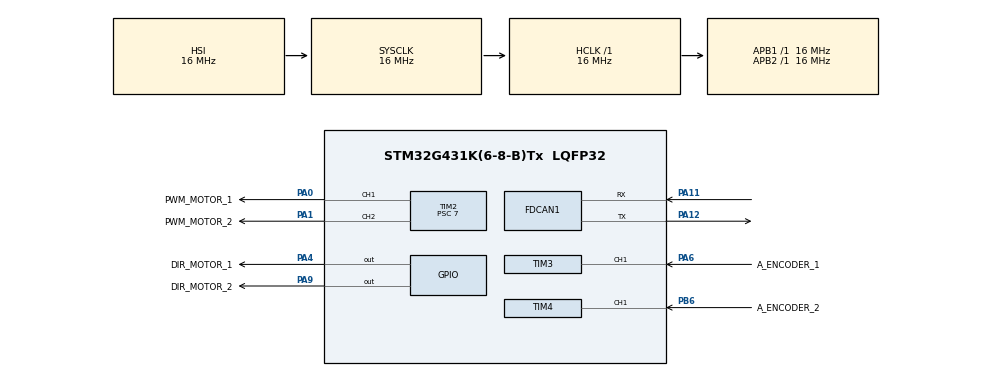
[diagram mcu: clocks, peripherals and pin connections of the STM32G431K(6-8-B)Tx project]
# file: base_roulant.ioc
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FDCAN1.CalculateBaudRateNominal=125000
FDCAN1.CalculateTimeBitNominal=8000
FDCAN1.CalculateTimeQuantumNominal=1000.0
FDCAN1.ClockDivider=FDCAN_CLOCK_DIV2
FDCAN1.NominalPrescaler=8
FDCAN1.NominalTimeSeg1=3
FDCAN1.NominalTimeSeg2=4
FDCAN1.StdFiltersNbr=1
Mcu.Family=STM32G4
Mcu.Name=STM32G431K(6-8-B)Tx
Mcu.Package=LQFP32
NVIC.PriorityGroup=NVIC_PRIORITYGROUP_4
NVIC.TIM1_UP_TIM16_IRQn=true\:0\:0\:true\:false\:true\:true\:true\:true
NVIC.TIM3_IRQn=true\:0\:0\:true\:false\:true\:true\:true\:true
NVIC.TIM4_IRQn=true\:0\:0\:true\:false\:true\:true\:true\:true
PA0.GPIO_Label=PWM_MOTOR_1
PA0.Signal=S_TIM2_CH1
PA1.GPIO_Label=PWM_MOTOR_2
PA1.Signal=S_TIM2_CH2
PA11.Mode=FDCAN_Activate
PA11.Signal=FDCAN1_RX
PA12.Mode=FDCAN_Activate
PA12.Signal=FDCAN1_TX
PA4.GPIO_Label=DIR_MOTOR_1
PA4.Signal=GPIO_Output
PA6.GPIO_Label=A_ENCODER_1
PA6.Signal=S_TIM3_CH1
PA9.GPIO_Label=DIR_MOTOR_2
PA9.Signal=GPIO_Output
PB6.GPIO_Label=A_ENCODER_2
PB6.Signal=S_TIM4_CH1
ProjectManager.HeapSize=0x200
ProjectManager.StackSize=0x400
ProjectManager.TargetToolchain=STM32CubeIDE
RCC.AHBFreq_Value=16000000
RCC.APB1Freq_Value=16000000
RCC.APB1TimFreq_Value=16000000
RCC.APB2Freq_Value=16000000
RCC.APB2TimFreq_Value=16000000
RCC.CortexFreq_Value=16000000
RCC.EXTERNAL_CLOCK_VALUE=12288000
RCC.HCLKFreq_Value=16000000
RCC.HSE_VALUE=8000000
RCC.HSI48_VALUE=48000000
RCC.HSI_VALUE=16000000
RCC.LSE_VALUE=32768
RCC.SYSCLKFreq_VALUE=16000000
RCC.USBFreq_Value=64000000
RCC.VCOOutputFreq_Value=128000000
SH.S_TIM2_CH1.0=TIM2_CH1,PWM Generation1 CH1
SH.S_TIM2_CH2.0=TIM2_CH2,PWM Generation2 CH2
SH.S_TIM3_CH1.0=TIM3_CH1,Input_Capture1_from_TI1
SH.S_TIM4_CH1.0=TIM4_CH1,Input_Capture1_from_TI1
TIM1.PeriodNoDither=3999
TIM1.Prescaler=2
TIM2.Channel-PWM\ Generation1\ CH1=TIM_CHANNEL_1
TIM2.Channel-PWM\ Generation2\ CH2=TIM_CHANNEL_2
TIM2.PeriodNoDither=99
TIM2.Prescaler=7
TIM3.Channel-Input_Capture1_from_TI1=TIM_CHANNEL_1
TIM3.Prescaler=127
TIM4.Channel-Input_Capture1_from_TI1=TIM_CHANNEL_1
TIM4.Prescaler=127
VP_SYS_VS_DBSignals.Mode=DisableDeadBatterySignals
VP_TIM1_VS_ClockSourceINT.Mode=Internal
VP_TIM2_VS_ClockSourceINT.Mode=Internal
board=custom

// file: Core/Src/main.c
/* USER CODE BEGIN Header */
/**
  ******************************************************************************
  * @file           : main.c
  * @brief          : Main program body
  ******************************************************************************
  * @attention
  *
  * Copyright (c) 2023 STMicroelectronics.
  * All rights reserved.
  *
  * This software is licensed under terms that can be found in the LICENSE file
  * in the root directory of this software component.
  * If no LICENSE file comes with this software, it is provided AS-IS.
  *
  ******************************************************************************
  */
/* USER CODE END Header */
#include "main.h"

/* USER CODE BEGIN Includes */
#include "base_roulant.h"
#include "can_stm32.h"
/* USER CODE END Includes */

/* USER CODE BEGIN PD */
#define TIM_CHANNEL_MOTOR_LEFT TIM_CHANNEL_1
#define TIM_CHANNEL_MOTOR_RIGHT TIM_CHANNEL_2

/* USER CODE END PD */

FDCAN_HandleTypeDef hfdcan1;

TIM_HandleTypeDef htim1;
TIM_HandleTypeDef htim2;
TIM_HandleTypeDef htim3;
TIM_HandleTypeDef htim4;

/* USER CODE BEGIN PV */
float s_left = 0;
float s_right = 0;

/* USER CODE END PV */

void SystemClock_Config(void);
static void MX_GPIO_Init(void);
static void MX_TIM2_Init(void);
static void MX_TIM3_Init(void);
static void MX_TIM4_Init(void);
static void MX_TIM1_Init(void);
static void MX_FDCAN1_Init(void);

/* USER CODE BEGIN 0 */
uint8_t dataTest[8] = {1,2,3,4,5,6,7,8};
/* USER CODE END 0 */

int main(void)
{

  /* MCU Configuration--------------------------------------------------------*/

  /* Reset of all peripherals, Initializes the Flash interface and the Systick. */
  HAL_Init();

  /* Configure the system clock */
  SystemClock_Config();

  /* Initialize all configured peripherals */
  MX_GPIO_Init();
  MX_TIM2_Init();
  MX_TIM3_Init();
  MX_TIM4_Init();
  MX_TIM1_Init();
  MX_FDCAN1_Init();
  /* USER CODE BEGIN 2 */
  BR_init(&htim1 ,&htim2, TIM_CHANNEL_MOTOR_LEFT, &htim2, TIM_CHANNEL_MOTOR_RIGHT, DIR_MOTOR_1_GPIO_Port, DIR_MOTOR_1_Pin, DIR_MOTOR_2_GPIO_Port, DIR_MOTOR_2_Pin, &htim3, &htim4, &hfdcan1);

  // Test sequence
  /*
  BR_setSpeed(BR_MOTOR_LEFT, 320.0);
  HAL_Delay(10000);
  BR_setSpeed(BR_MOTOR_LEFT, 20.0);
  HAL_Delay(30000);
  BR_setSpeed(BR_MOTOR_LEFT, 500.0);
  HAL_Delay(10000);
  BR_setSpeed(BR_MOTOR_LEFT, 0.0);
  HAL_Delay(10000);
	*/

  //BR_setPWM(BR_MOTOR_LEFT, 50);
  //BR_setPWM(BR_MOTOR_RIGHT, 50);
//  HAL_Delay(10000);

  //BR_setPWM(BR_MOTOR_LEFT, 30);
  //BR_setPWM(BR_MOTOR_RIGHT, 30);

//  s_left = BR_getSpeed(BR_MOTOR_LEFT);
//  s_right = BR_getSpeed(BR_MOTOR_RIGHT);
//
//  HAL_Delay(20000);
//
//  BR_stopAllMotors();

  /* USER CODE END 2 */

  /* Infinite loop */
  /* USER CODE BEGIN WHILE */
  while (1)
  {
	  //s_left = BR_getSpeed(BR_MOTOR_LEFT);
	  //s_right = BR_getSpeed(BR_MOTOR_RIGHT);

    /* Uncomment to ge CMD from CAN */
	  BR_getCMDfromCAN();
    /********************************/

	  //CAN_sendBackPing(CAN_ID_MASTER);
	  //CAN_send(dataTest, 0, 1);
	  HAL_Delay(10);
    /* USER CODE END WHILE */

  }
}

void SystemClock_Config(void)
{
  RCC_OscInitTypeDef RCC_OscInitStruct = {0};
  RCC_ClkInitTypeDef RCC_ClkInitStruct = {0};

  /** Configure the main internal regulator output voltage
  */
  HAL_PWREx_ControlVoltageScaling(PWR_REGULATOR_VOLTAGE_SCALE1);

  /** Initializes the RCC Oscillators according to the specified parameters
  * in the RCC_OscInitTypeDef structure.
  */
  RCC_OscInitStruct.OscillatorType = RCC_OSCILLATORTYPE_HSI;
  RCC_OscInitStruct.HSIState = RCC_HSI_ON;
  RCC_OscInitStruct.HSICalibrationValue = RCC_HSICALIBRATION_DEFAULT;
  RCC_OscInitStruct.PLL.PLLState = RCC_PLL_NONE;
  if (HAL_RCC_OscConfig(&RCC_OscInitStruct) != HAL_OK)
  {
    Error_Handler();
  }

  /** Initializes the CPU, AHB and APB buses clocks
  */
  RCC_ClkInitStruct.ClockType = RCC_CLOCKTYPE_HCLK|RCC_CLOCKTYPE_SYSCLK
                              |RCC_CLOCKTYPE_PCLK1|RCC_CLOCKTYPE_PCLK2;
  RCC_ClkInitStruct.SYSCLKSource = RCC_SYSCLKSOURCE_HSI;
  RCC_ClkInitStruct.AHBCLKDivider = RCC_SYSCLK_DIV1;
  RCC_ClkInitStruct.APB1CLKDivider = RCC_HCLK_DIV1;
  RCC_ClkInitStruct.APB2CLKDivider = RCC_HCLK_DIV1;

  if (HAL_RCC_ClockConfig(&RCC_ClkInitStruct, FLASH_LATENCY_0) != HAL_OK)
  {
    Error_Handler();
  }
}

static void MX_FDCAN1_Init(void)
{

  hfdcan1.Instance = FDCAN1;
  hfdcan1.Init.ClockDivider = FDCAN_CLOCK_DIV2;
  hfdcan1.Init.FrameFormat = FDCAN_FRAME_CLASSIC;
  hfdcan1.Init.Mode = FDCAN_MODE_NORMAL;
  hfdcan1.Init.AutoRetransmission = DISABLE;
  hfdcan1.Init.TransmitPause = DISABLE;
  hfdcan1.Init.ProtocolException = DISABLE;
  hfdcan1.Init.NominalPrescaler = 8;
  hfdcan1.Init.NominalSyncJumpWidth = 1;
  hfdcan1.Init.NominalTimeSeg1 = 3;
  hfdcan1.Init.NominalTimeSeg2 = 4;
  hfdcan1.Init.DataPrescaler = 1;
  hfdcan1.Init.DataSyncJumpWidth = 1;
  hfdcan1.Init.DataTimeSeg1 = 1;
  hfdcan1.Init.DataTimeSeg2 = 1;
  hfdcan1.Init.StdFiltersNbr = 1;
  hfdcan1.Init.ExtFiltersNbr = 0;
  hfdcan1.Init.TxFifoQueueMode = FDCAN_TX_FIFO_OPERATION;
  if (HAL_FDCAN_Init(&hfdcan1) != HAL_OK)
  {
    Error_Handler();
  }

}

static void MX_TIM1_Init(void)
{

  TIM_ClockConfigTypeDef sClockSourceConfig = {0};
  TIM_MasterConfigTypeDef sMasterConfig = {0};

  htim1.Instance = TIM1;
  htim1.Init.Prescaler = 2;
  htim1.Init.CounterMode = TIM_COUNTERMODE_UP;
  htim1.Init.Period = 3999;
  htim1.Init.ClockDivision = TIM_CLOCKDIVISION_DIV1;
  htim1.Init.RepetitionCounter = 0;
  htim1.Init.AutoReloadPreload = TIM_AUTORELOAD_PRELOAD_DISABLE;
  if (HAL_TIM_Base_Init(&htim1) != HAL_OK)
  {
    Error_Handler();
  }
  sClockSourceConfig.ClockSource = TIM_CLOCKSOURCE_INTERNAL;
  if (HAL_TIM_ConfigClockSource(&htim1, &sClockSourceConfig) != HAL_OK)
  {
    Error_Handler();
  }
  sMasterConfig.MasterOutputTrigger = TIM_TRGO_RESET;
  sMasterConfig.MasterOutputTrigger2 = TIM_TRGO2_RESET;
  sMasterConfig.MasterSlaveMode = TIM_MASTERSLAVEMODE_DISABLE;
  if (HAL_TIMEx_MasterConfigSynchronization(&htim1, &sMasterConfig) != HAL_OK)
  {
    Error_Handler();
  }

}

static void MX_TIM2_Init(void)
{

  TIM_ClockConfigTypeDef sClockSourceConfig = {0};
  TIM_MasterConfigTypeDef sMasterConfig = {0};
  TIM_OC_InitTypeDef sConfigOC = {0};

  htim2.Instance = TIM2;
  htim2.Init.Prescaler = 7;
  htim2.Init.CounterMode = TIM_COUNTERMODE_UP;
  htim2.Init.Period = 99;
  htim2.Init.ClockDivision = TIM_CLOCKDIVISION_DIV1;
  htim2.Init.AutoReloadPreload = TIM_AUTORELOAD_PRELOAD_DISABLE;
  if (HAL_TIM_Base_Init(&htim2) != HAL_OK)
  {
    Error_Handler();
  }
  sClockSourceConfig.ClockSource = TIM_CLOCKSOURCE_INTERNAL;
  if (HAL_TIM_ConfigClockSource(&htim2, &sClockSourceConfig) != HAL_OK)
  {
    Error_Handler();
  }
  if (HAL_TIM_PWM_Init(&htim2) != HAL_OK)
  {
    Error_Handler();
  }
  sMasterConfig.MasterOutputTrigger = TIM_TRGO_RESET;
  sMasterConfig.MasterSlaveMode = TIM_MASTERSLAVEMODE_DISABLE;
  if (HAL_TIMEx_MasterConfigSynchronization(&htim2, &sMasterConfig) != HAL_OK)
  {
    Error_Handler();
  }
  sConfigOC.OCMode = TIM_OCMODE_PWM1;
  sConfigOC.Pulse = 0;
  sConfigOC.OCPolarity = TIM_OCPOLARITY_HIGH;
  sConfigOC.OCFastMode = TIM_OCFAST_DISABLE;
  if (HAL_TIM_PWM_ConfigChannel(&htim2, &sConfigOC, TIM_CHANNEL_1) != HAL_OK)
  {
    Error_Handler();
  }
  if (HAL_TIM_PWM_ConfigChannel(&htim2, &sConfigOC, TIM_CHANNEL_2) != HAL_OK)
  {
    Error_Handler();
  }
  HAL_TIM_MspPostInit(&htim2);

}

static void MX_TIM3_Init(void)
{

  TIM_MasterConfigTypeDef sMasterConfig = {0};
  TIM_IC_InitTypeDef sConfigIC = {0};

  htim3.Instance = TIM3;
  htim3.Init.Prescaler = 127;
  htim3.Init.CounterMode = TIM_COUNTERMODE_UP;
  htim3.Init.Period = 65535;
  htim3.Init.ClockDivision = TIM_CLOCKDIVISION_DIV1;
  htim3.Init.AutoReloadPreload = TIM_AUTORELOAD_PRELOAD_DISABLE;
  if (HAL_TIM_IC_Init(&htim3) != HAL_OK)
  {
    Error_Handler();
  }
  sMasterConfig.MasterOutputTrigger = TIM_TRGO_RESET;
  sMasterConfig.MasterSlaveMode = TIM_MASTERSLAVEMODE_DISABLE;
  if (HAL_TIMEx_MasterConfigSynchronization(&htim3, &sMasterConfig) != HAL_OK)
  {
    Error_Handler();
  }
  sConfigIC.ICPolarity = TIM_INPUTCHANNELPOLARITY_RISING;
  sConfigIC.ICSelection = TIM_ICSELECTION_DIRECTTI;
  sConfigIC.ICPrescaler = TIM_ICPSC_DIV1;
  sConfigIC.ICFilter = 0;
  if (HAL_TIM_IC_ConfigChannel(&htim3, &sConfigIC, TIM_CHANNEL_1) != HAL_OK)
  {
    Error_Handler();
  }

}

static void MX_TIM4_Init(void)
{

  TIM_MasterConfigTypeDef sMasterConfig = {0};
  TIM_IC_InitTypeDef sConfigIC = {0};

  htim4.Instance = TIM4;
  htim4.Init.Prescaler = 127;
  htim4.Init.CounterMode = TIM_COUNTERMODE_UP;
  htim4.Init.Period = 65535;
  htim4.Init.ClockDivision = TIM_CLOCKDIVISION_DIV1;
  htim4.Init.AutoReloadPreload = TIM_AUTORELOAD_PRELOAD_DISABLE;
  if (HAL_TIM_IC_Init(&htim4) != HAL_OK)
  {
    Error_Handler();
  }
  sMasterConfig.MasterOutputTrigger = TIM_TRGO_RESET;
  sMasterConfig.MasterSlaveMode = TIM_MASTERSLAVEMODE_DISABLE;
  if (HAL_TIMEx_MasterConfigSynchronization(&htim4, &sMasterConfig) != HAL_OK)
  {
    Error_Handler();
  }
  sConfigIC.ICPolarity = TIM_INPUTCHANNELPOLARITY_RISING;
  sConfigIC.ICSelection = TIM_ICSELECTION_DIRECTTI;
  sConfigIC.ICPrescaler = TIM_ICPSC_DIV1;
  sConfigIC.ICFilter = 0;
  if (HAL_TIM_IC_ConfigChannel(&htim4, &sConfigIC, TIM_CHANNEL_1) != HAL_OK)
  {
    Error_Handler();
  }

}

static void MX_GPIO_Init(void)
{
  GPIO_InitTypeDef GPIO_InitStruct = {0};

  /* GPIO Ports Clock Enable */
  __HAL_RCC_GPIOA_CLK_ENABLE();
  __HAL_RCC_GPIOB_CLK_ENABLE();

  /*Configure GPIO pin Output Level */
  HAL_GPIO_WritePin(GPIOA, DIR_MOTOR_1_Pin|DIR_MOTOR_2_Pin, GPIO_PIN_RESET);

  /*Configure GPIO pins : DIR_MOTOR_1_Pin DIR_MOTOR_2_Pin */
  GPIO_InitStruct.Pin = DIR_MOTOR_1_Pin|DIR_MOTOR_2_Pin;
  GPIO_InitStruct.Mode = GPIO_MODE_OUTPUT_PP;
  GPIO_InitStruct.Pull = GPIO_NOPULL;
  GPIO_InitStruct.Speed = GPIO_SPEED_FREQ_LOW;
  HAL_GPIO_Init(GPIOA, &GPIO_InitStruct);

}

void Error_Handler(void)
{
  __disable_irq();
  while (1)
  {
  }
}
